# STM32C092 register map
File version: 1.2
CPU: CM0+ r0p0, little endian, MPU, no FPU, 4 interrupt priority bits
Registers are 32-bit, read-write, reset 0x0 unless marked. A register's access mark holds for its fields unless they carry their own. Offsets are from the block's base; [hi:lo] are bit positions; {n}, {i} and the like mark numbered series; 'fields as' and 'values as' point back to an identical list.

## EXTI — EXTI address block description
Base 0x40021800
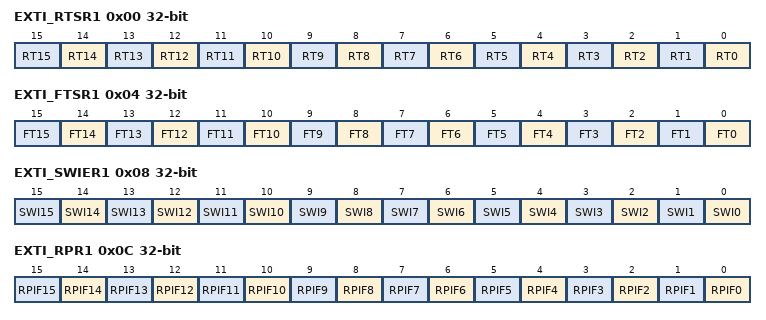
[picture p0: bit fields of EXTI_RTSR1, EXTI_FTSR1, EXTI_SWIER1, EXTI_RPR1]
0x00 EXTI_RTSR1 — EXTI rising trigger selection register 1
  [all] fields
    0=Disable; 1=Enable
  [n] RT{n} (n=0..15) — Rising trigger event configuration bit of configurable line x (x = 15 to 0) Each bit enables/disables the rising edge trigger for the event and interrupt on the corresponding line. Note: The configurable lines are edge triggered; no glitch must be generated on these inputs. If a rising edge on the configurable line occurs during writing of the register, the associated pending bit is not set. Rising edge trigger can be set for a line with falling edge trigger enabled. In this case, both edges generate a trigger.
0x04 EXTI_FTSR1 — EXTI falling trigger selection register 1
  [all] fields
    0=Disable; 1=Enable
  [n] FT{n} (n=0..15) — Falling trigger event configuration bit of configurable line x (x = 15 to 0). Each bit enables/disables the falling edge trigger for the event and interrupt on the corresponding line. The configurable lines are edge triggered; no glitch must be generated on these inputs. Note: If a falling edge on the configurable line occurs during writing of the register, the associated pending bit is not set. Falling edge trigger can be set for a line with rising edge trigger enabled. In this case, both edges generate a trigger.
0x08 EXTI_SWIER1 — EXTI software interrupt event register 1
  [all] fields
    0=No effect; 1=Rising edge event generated on the corresponding line, followed by an interrupt
  [n] SWI{n} (n=0..15) — Software rising edge event trigger on line x (x = 15 to 0) Setting of any bit by software triggers a rising edge event on the corresponding line x, resulting in an interrupt, independently of EXTI_RTSR1 and EXTI_FTSR1 settings. The bits are automatically cleared by HW. Reading of any bit always returns 0.
0x0C EXTI_RPR1 — EXTI rising edge pending register 1
  [all] fields
    0=No rising edge trigger request occurred; 1=Rising edge trigger request occurred
  [n] RPIF{n} (n=0..15) — Rising edge event pending for configurable line x (x = 15 to 0) Each bit is set upon a rising edge event generated by hardware or by software (through the EXTI_SWIER1 register) on the corresponding line. Each bit is cleared by writing 1 into it.
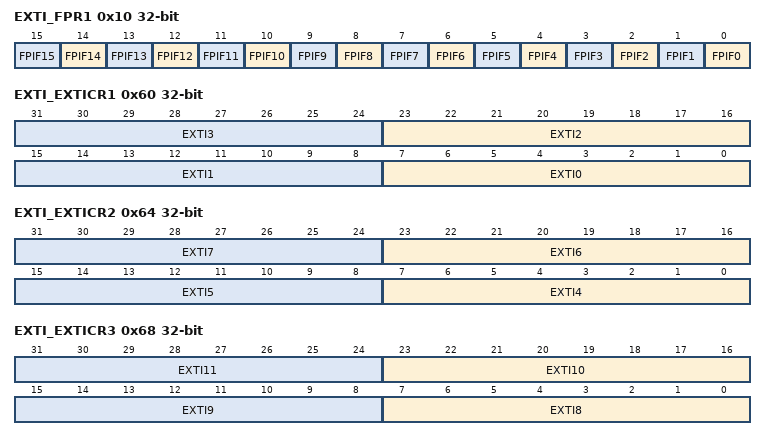
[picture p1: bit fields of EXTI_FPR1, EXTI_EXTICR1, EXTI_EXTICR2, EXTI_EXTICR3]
0x10 EXTI_FPR1 — EXTI falling edge pending register 1
  [all] fields
    0=No falling edge trigger request occurred; 1=Falling edge trigger request occurred
  [n] FPIF{n} (n=0..15) — Falling edge event pending for configurable line x (x = 15 to 0) Each bit is set upon a falling edge event generated by hardware or by software (through the EXTI_SWIER1 register) on the corresponding line. Each bit is cleared by writing 1 into it.
0x28 EXTI_RTSR2 — EXTI rising trigger selection register 2
  [2] RT34 — Rising trigger event configuration bit of configurable line 34 Each bit enables/disables the rising edge trigger for the event and interrupt on the line 34. This configurable line is edge triggered; no glitch must be generated on this inputs. Note: If a rising edge on the configurable line occurs during writing of the register, the associated pending bit is not set. Rising edge trigger can be set for a line with falling edge trigger enabled. In this case, both edges generate a trigger.
    0=Disable; 1=Enable
0x2C EXTI_FTSR2 — EXTI falling trigger selection register 2
  [2] FT34 — Falling trigger event configuration bit of configurable line 34. Each bit enables/disables the falling edge trigger for the event and interrupt on the line 34. The configurable lines are edge triggered; no glitch must be generated on these inputs. Note: If a falling edge on the configurable line occurs during writing of the register, the associated pending bit is not set. Falling edge trigger can be set for a line with rising edge trigger enabled. In this case, both edges generate a trigger.
    0=Disable; 1=Enable
0x30 EXTI_SWIER2 — EXTI software interrupt event register 2
  [2] SWI34 — Software rising edge event trigger on line 34 Setting of any bit by software triggers a rising edge event on the line 34, resulting in an interrupt, independently of EXTI_RTSR2 and EXTI_FTSR2 settings. The bits are automatically cleared by HW. Reading of any bit always returns 0.
    values as the fields of EXTI_SWIER1
0x34 EXTI_RPR2 — EXTI rising edge pending register 2
  [2] RPIF34 — Rising edge event pending for configurable line 34 Each bit is set upon a rising edge event generated by hardware or by software (through the EXTI_SWIER2 register) on the line 34. Each bit is cleared by writing 1 into it.
    values as the fields of EXTI_RPR1
0x38 EXTI_FPR2 — EXTI falling edge pending register 2
  [2] FPIF34 — Falling edge event pending for configurable line 34 Each bit is set upon a falling edge event generated by hardware or by software (through the EXTI_SWIER2 register) on the line 34. Each bit is cleared by writing 1 into it.
    values as the fields of EXTI_FPR1
0x60 EXTI_EXTICR1 — EXTI external interrupt selection register
  [8n+7:8n] EXTI{n} (n=0..3) — EXTI{n} GPIO port selection These bits are written by software to select the source input for EXTI{n} external interrupt. Others reserved
    0=PA[{n}] pin; 1=PB[{n}] pin; 2=PC[{n}] pin; 3=PD[{n}] pin; 5=PF[{n}] pin
0x64 EXTI_EXTICR2 — EXTI external interrupt selection register
  [8n-25:8n-32] EXTI{n} (n=4..7) — EXTI{n} GPIO port selection These bits are written by software to select the source input for EXTI{n} external interrupt. Others reserved
    values as EXTI_EXTICR1.EXTI0
0x68 EXTI_EXTICR3 — EXTI external interrupt selection register
  [8n-57:8n-64] EXTI{n} (n=8..11) — EXTI{n} GPIO port selection These bits are written by software to select the source input for EXTI{n} external interrupt. Others reserved
    values as EXTI_EXTICR1.EXTI0
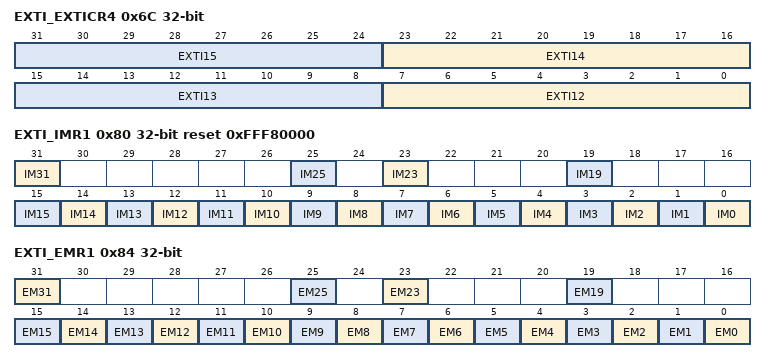
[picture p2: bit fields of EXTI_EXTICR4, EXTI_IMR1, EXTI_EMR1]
0x6C EXTI_EXTICR4 — EXTI external interrupt selection register
  [8n-89:8n-96] EXTI{n} (n=12..15) — EXTI{n} GPIO port selection These bits are written by software to select the source input for EXTI{n} external interrupt. Others reserved
    values as EXTI_EXTICR1.EXTI0
0x80 EXTI_IMR1 reset 0xFFF80000 — EXTI CPU wakeup with interrupt mask register 1
  [all] fields
    0=wakeup with interrupt masked; 1=wakeup with interrupt unmasked
  [31] IM31 — CPU wakeup with interrupt mask on line 31 Setting/clearing this bit unmasks/masks the CPU wakeup with interrupt, by an event on the corresponding line.
  [25] IM25 — CPU wakeup with interrupt mask on line 25 Setting/clearing each bit unmasks/masks the CPU wakeup with interrupt, by an event on the corresponding line.
  [23] IM23 — CPU wakeup with interrupt mask on line 23 Setting/clearing each bit unmasks/masks the CPU wakeup with interrupt, by an event on the corresponding line.
  [19] IM19 — CPU wakeup with interrupt mask on line 19 Setting/clearing this bit unmasks/masks the CPU wakeup with interrupt, by an event on the corresponding line.
  [n] IM{n} (n=0..15) — CPU wakeup with interrupt mask on line x (x = 15 to 0) Setting/clearing each bit unmasks/masks the CPU wakeup with interrupt, by an event on the corresponding line.
0x84 EXTI_EMR1 — EXTI CPU wakeup with event mask register
  [all] fields
    0=wakeup with event generation masked; 1=wakeup with event generation unmasked
  [31] EM31 — CPU wakeup with event generation mask on line 31 Setting/clearing this bit unmasks/masks the CPU wakeup with event generation on the corresponding line.
  [25] EM25 — CPU wakeup with event generation mask on line 25 Setting/clearing this bit unmasks/masks the CPU wakeup with event generation on the corresponding line.
  [23] EM23 — CPU wakeup with event generation mask on line 23 Setting/clearing this bit unmasks/masks the CPU wakeup with event generation on the corresponding line.
  [19] EM19 — CPU wakeup with event generation mask on line 19 Setting/clearing this bit unmasks/masks the CPU wakeup with event generation on the corresponding line.
  [n] EM{n} (n=0..15) — CPU wakeup with event generation mask on line x (x = 15 to 0) Setting/clearing each bit unmasks/masks the CPU wakeup with event generation on the corresponding line.
0x90 EXTI_IMR2 — EXTI CPU wakeup with interrupt mask register 2
  [2] IM34 — CPU wakeup with interrupt mask on line 34 Setting/clearing the bit unmasks/masks the CPU wakeup with interrupt request from the line 34.
    values as the fields of EXTI_IMR1
0x94 EXTI_EMR2 — EXTI CPU wakeup with event mask register 2
  [2] EM34 — CPU wakeup with event generation mask on line 34 Setting/clearing this bit unmasks/masks the CPU wakeup with event generation on the line 34.
    values as the fields of EXTI_EMR1
